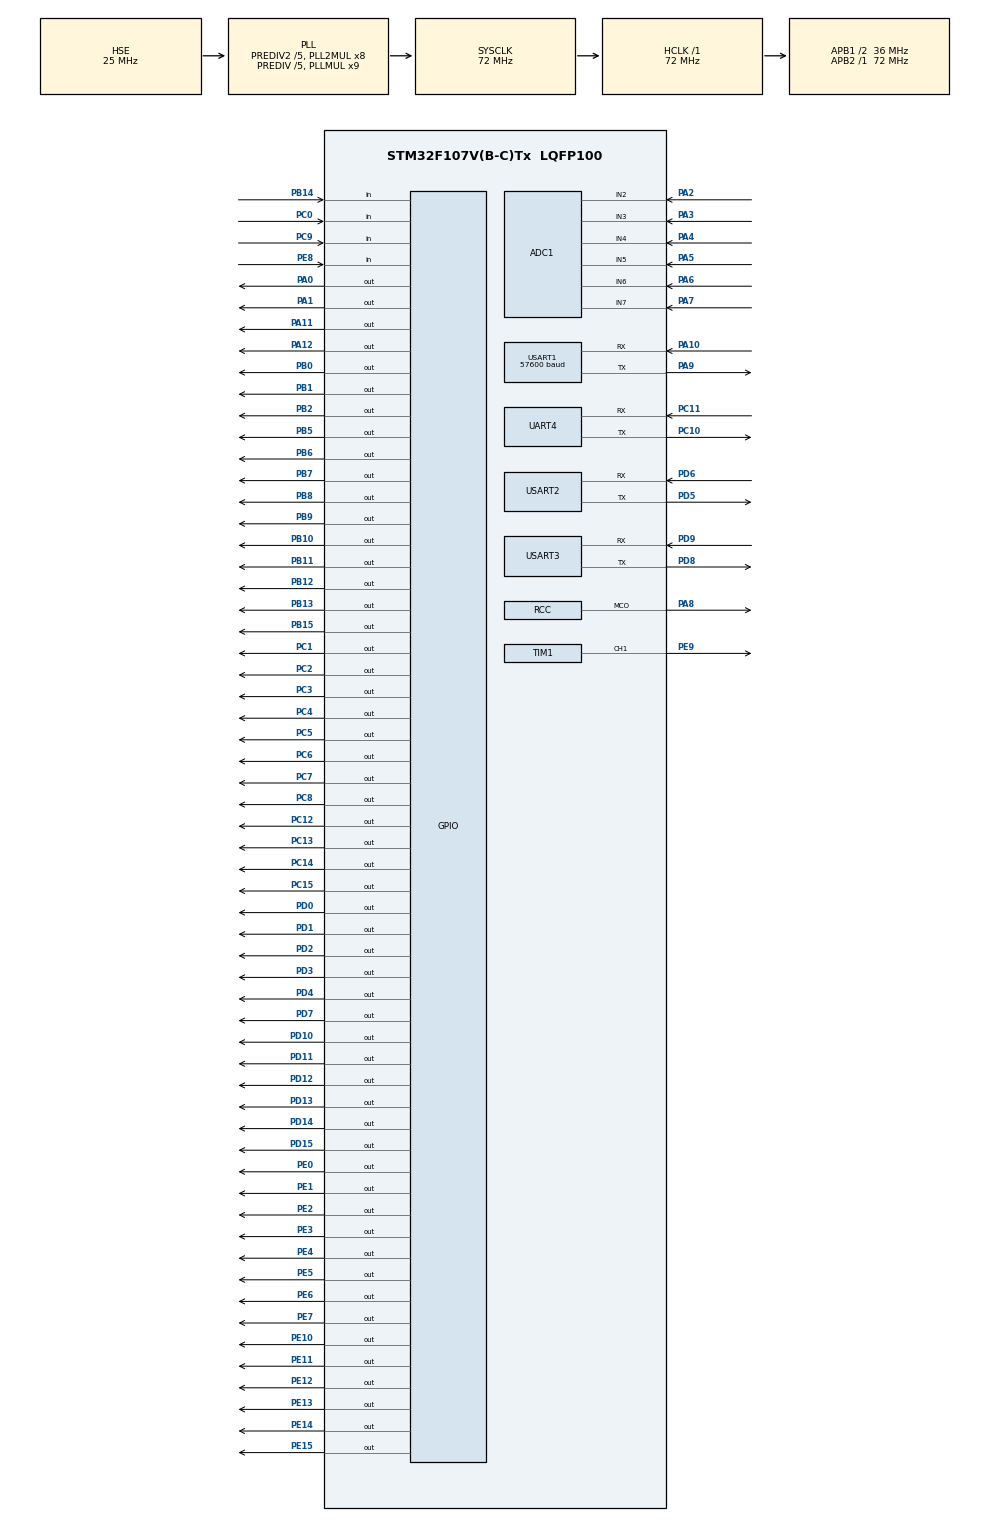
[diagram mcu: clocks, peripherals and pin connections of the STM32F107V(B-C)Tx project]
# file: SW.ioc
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ADC1.Channel-10\#ChannelRegularConversion=ADC_CHANNEL_6
ADC1.Channel-11\#ChannelRegularConversion=ADC_CHANNEL_7
ADC1.Channel-6\#ChannelRegularConversion=ADC_CHANNEL_2
ADC1.Channel-7\#ChannelRegularConversion=ADC_CHANNEL_3
ADC1.Channel-8\#ChannelRegularConversion=ADC_CHANNEL_4
ADC1.Channel-9\#ChannelRegularConversion=ADC_CHANNEL_5
ADC1.ContinuousConvMode=ENABLE
ADC1.EnableRegularConversion=ENABLE
ADC1.NbrOfConversion=6
ADC1.NbrOfConversionFlag=1
ADC1.Rank-10\#ChannelRegularConversion=5
ADC1.Rank-11\#ChannelRegularConversion=6
ADC1.Rank-6\#ChannelRegularConversion=1
ADC1.Rank-7\#ChannelRegularConversion=2
ADC1.Rank-8\#ChannelRegularConversion=3
ADC1.Rank-9\#ChannelRegularConversion=4
ADC1.SamplingTime-10\#ChannelRegularConversion=ADC_SAMPLETIME_41CYCLES_5
ADC1.SamplingTime-11\#ChannelRegularConversion=ADC_SAMPLETIME_41CYCLES_5
ADC1.SamplingTime-6\#ChannelRegularConversion=ADC_SAMPLETIME_41CYCLES_5
ADC1.SamplingTime-7\#ChannelRegularConversion=ADC_SAMPLETIME_41CYCLES_5
ADC1.SamplingTime-8\#ChannelRegularConversion=ADC_SAMPLETIME_41CYCLES_5
ADC1.SamplingTime-9\#ChannelRegularConversion=ADC_SAMPLETIME_41CYCLES_5
ADC1.master=1
Dma.ADC1.0.Direction=DMA_PERIPH_TO_MEMORY
Dma.ADC1.0.Instance=DMA1_Channel1
Dma.ADC1.0.MemDataAlignment=DMA_MDATAALIGN_WORD
Dma.ADC1.0.MemInc=DMA_MINC_ENABLE
Dma.ADC1.0.Mode=DMA_CIRCULAR
Dma.ADC1.0.PeriphDataAlignment=DMA_PDATAALIGN_WORD
Dma.ADC1.0.PeriphInc=DMA_PINC_DISABLE
Dma.ADC1.0.Priority=DMA_PRIORITY_LOW
Dma.Request0=ADC1
Mcu.Family=STM32F1
Mcu.Name=STM32F107V(B-C)Tx
Mcu.Package=LQFP100
NVIC.DMA1_Channel1_IRQn=true\:0\:0\:false\:false\:true\:true\:true
NVIC.PriorityGroup=NVIC_PRIORITYGROUP_4
NVIC.TIM3_IRQn=true\:0\:0\:false\:false\:true\:true\:true
NVIC.UART4_IRQn=true\:1\:0\:true\:true\:true\:2\:true\:true
NVIC.USART1_IRQn=true\:0\:0\:true\:true\:true\:1\:true\:true
NVIC.USART2_IRQn=true\:1\:0\:true\:true\:true\:3\:true\:true
NVIC.USART3_IRQn=true\:0\:0\:false\:true\:true\:4\:true\:true
OSC_IN.Mode=HSE-External-Oscillator
OSC_IN.Signal=RCC_OSC_IN
OSC_OUT.Mode=HSE-External-Oscillator
OSC_OUT.Signal=RCC_OSC_OUT
PA0-WKUP.Signal=GPIO_Output
PA1.Signal=GPIO_Output
PA10.Mode=Asynchronous
PA10.Signal=USART1_RX
PA11.Signal=GPIO_Output
PA12.Signal=GPIO_Output
PA13.Mode=Serial_Wire
PA13.Signal=SYS_JTMS-SWDIO
PA14.Mode=Serial_Wire
PA14.Signal=SYS_JTCK-SWCLK
PA15.Signal=SYS_JTDI
PA2.Signal=ADCx_IN2
PA3.Signal=ADCx_IN3
PA4.Signal=ADCx_IN4
PA5.Signal=ADCx_IN5
PA6.Signal=ADCx_IN6
PA7.Signal=ADCx_IN7
PA8.Mode=Clock-out
PA8.Signal=RCC_MCO
PA9.Mode=Asynchronous
PA9.Signal=USART1_TX
PB0.Signal=GPIO_Output
PB1.Signal=GPIO_Output
PB10.Signal=GPIO_Output
PB11.Signal=GPIO_Output
PB12.Signal=GPIO_Output
PB13.Signal=GPIO_Output
PB14.Signal=GPIO_Input
PB15.Signal=GPIO_Output
PB2.Signal=GPIO_Output
PB3.Signal=SYS_JTDO
PB4.Signal=SYS_NJTRST
PB5.Signal=GPIO_Output
PB6.Signal=GPIO_Output
PB7.Signal=GPIO_Output
PB8.Signal=GPIO_Output
PB9.Signal=GPIO_Output
PC0.Signal=GPIO_Input
PC1.Signal=GPIO_Output
PC10.Mode=Asynchronous
PC10.Signal=UART4_TX
PC11.Mode=Asynchronous
PC11.Signal=UART4_RX
PC12.Signal=GPIO_Output
PC13-TAMPER-RTC.Signal=GPIO_Output
PC14-OSC32_IN.Signal=GPIO_Output
PC15-OSC32_OUT.Signal=GPIO_Output
PC2.Signal=GPIO_Output
PC3.Signal=GPIO_Output
PC4.Signal=GPIO_Output
PC5.Signal=GPIO_Output
PC6.Signal=GPIO_Output
PC7.Signal=GPIO_Output
PC8.Signal=GPIO_Output
PC9.Signal=GPIO_Input
PD0.Signal=GPIO_Output
PD1.Signal=GPIO_Output
PD10.Signal=GPIO_Output
PD11.Signal=GPIO_Output
PD12.Signal=GPIO_Output
PD13.Signal=GPIO_Output
PD14.Signal=GPIO_Output
PD15.Signal=GPIO_Output
PD2.Signal=GPIO_Output
PD3.Signal=GPIO_Output
PD4.Signal=GPIO_Output
PD5.Mode=Asynchronous
PD5.Signal=USART2_TX
PD6.Mode=Asynchronous
PD6.Signal=USART2_RX
PD7.Signal=GPIO_Output
PD8.Mode=Asynchronous
PD8.Signal=USART3_TX
PD9.Mode=Asynchronous
PD9.Signal=USART3_RX
PE0.Signal=GPIO_Output
PE1.Signal=GPIO_Output
PE10.Signal=GPIO_Output
PE11.Signal=GPIO_Output
PE12.Signal=GPIO_Output
PE13.Signal=GPIO_Output
PE14.Signal=GPIO_Output
PE15.Signal=GPIO_Output
PE2.Signal=GPIO_Output
PE3.Signal=GPIO_Output
PE4.Signal=GPIO_Output
PE5.Signal=GPIO_Output
PE6.Signal=GPIO_Output
PE7.Signal=GPIO_Output
PE8.Signal=GPIO_Input
PE9.Signal=S_TIM1_CH1
ProjectManager.HeapSize=0x200
ProjectManager.StackSize=0x400
ProjectManager.TargetToolchain=MDK-ARM V5.27
RCC.ADCPresc=RCC_ADCPCLK2_DIV6
RCC.AHBFreq_Value=72000000
RCC.APB1CLKDivider=RCC_HCLK_DIV2
RCC.APB1Freq_Value=36000000
RCC.APB1TimFreq_Value=72000000
RCC.APB2Freq_Value=72000000
RCC.APB2TimFreq_Value=72000000
RCC.HCLKFreq_Value=72000000
RCC.HSEDivPLL=RCC_HSE_PREDIV_DIV5
RCC.HSE_VALUE=25000000
RCC.PLLMUL=RCC_PLL_MUL9
RCC.PLLSourceVirtual=RCC_PLLSOURCE_HSE
RCC.Prediv1Source=RCC_PREDIV1_SOURCE_PLL2
RCC.Prediv2=RCC_HSE_PREDIV2_DIV5
RCC.RCC_MCOSource=RCC_MCO1SOURCE_HSE
RCC.SYSCLKFreq_VALUE=72000000
RCC.SYSCLKSource=RCC_SYSCLKSOURCE_PLLCLK
RCC.USBFreq_Value=48000000
SH.ADCx_IN2.0=ADC1_IN2,IN2
SH.ADCx_IN3.0=ADC1_IN3,IN3
SH.ADCx_IN4.0=ADC1_IN4,IN4
SH.ADCx_IN5.0=ADC1_IN5,IN5
SH.ADCx_IN6.0=ADC1_IN6,IN6
SH.ADCx_IN7.0=ADC1_IN7,IN7
SH.S_TIM1_CH1.0=TIM1_CH1,PWM Generation1 CH1
TIM1.Channel-PWM\ Generation1\ CH1=TIM_CHANNEL_1
TIM3.Period=1500
TIM3.Prescaler=65000
UART4.VirtualMode=Asynchronous
USART1.BaudRate=57600
USART1.VirtualMode=VM_ASYNC
USART2.VirtualMode=VM_ASYNC
USART3.VirtualMode=VM_ASYNC
VP_TIM1_VS_ClockSourceINT.Mode=Internal
VP_TIM2_VS_ClockSourceINT.Mode=Internal
VP_TIM3_VS_ClockSourceINT.Mode=Internal
board=custom

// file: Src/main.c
/* USER CODE BEGIN Header */
/**
  ******************************************************************************
  * @file           : main.c
  * @brief          : Main program body
  ******************************************************************************
  * @attention
  *
  * <h2><center>&copy; Copyright (c) 2020 STMicroelectronics.
  * All rights reserved.</center></h2>
  *
  * This software component is licensed by ST under BSD 3-Clause license,
  * the "License"; You may not use this file except in compliance with the
  * License. You may obtain a copy of the License at:
  *                        opensource.org/licenses/BSD-3-Clause
  *
  ******************************************************************************
  */
/* USER CODE END Header */

#include "main.h"

/* USER CODE BEGIN Includes */
#include "bat.h"
#include "COM.h"
#include <stdio.h>
#include "motor.h"
#include "CMDHandler.h"
#include "lora.h"
/* USER CODE END Includes */

/* USER CODE BEGIN PD */

#define true 1
#define false 0

/* USER CODE END PD */

ADC_HandleTypeDef hadc1;
DMA_HandleTypeDef hdma_adc1;

TIM_HandleTypeDef htim1;
TIM_HandleTypeDef htim2;
TIM_HandleTypeDef htim3;

UART_HandleTypeDef huart4;
UART_HandleTypeDef huart1;
UART_HandleTypeDef huart2;
UART_HandleTypeDef huart3;

void SystemClock_Config(void);
static void MX_GPIO_Init(void);
static void MX_DMA_Init(void);
static void MX_ADC1_Init(void);
static void MX_TIM1_Init(void);
static void MX_UART4_Init(void);
static void MX_USART1_UART_Init(void);
static void MX_USART2_UART_Init(void);
static void MX_TIM2_Init(void);
static void MX_USART3_UART_Init(void);
static void MX_TIM3_Init(void);
static void MX_NVIC_Init(void);

/* USER CODE BEGIN 0 */
		//uint8_t rx_buff[1];
		char rx_ard_buff[1];
		char rx_add_buff[1];
		char rx_lora_buff[1];
		char rx_com_buff[1];
		uint32_t ADCvalues[6];
/* USER CODE END 0 */

int main(void)
{

  /* MCU Configuration--------------------------------------------------------*/

  /* Reset of all peripherals, Initializes the Flash interface and the Systick. */
  HAL_Init();

  /* Configure the system clock */
  SystemClock_Config();

  /* Initialize all configured peripherals */
  MX_GPIO_Init();
	MX_TIM3_Init();
  MX_DMA_Init();
  MX_ADC1_Init();
  MX_TIM1_Init();
  MX_UART4_Init();
  MX_USART1_UART_Init();
  MX_USART2_UART_Init();
  MX_TIM2_Init();
  MX_USART3_UART_Init();

  /* Initialize interrupts */
  MX_NVIC_Init();
  /* USER CODE BEGIN 2 */

	_Bool BATOKAY = false;

	//BatLED(0x3F);
	COM_TX("START\r\n");

	HAL_ADC_Start_DMA(&hadc1,(uint32_t *)ADCvalues, 6);
	//HAL_ADC_Start(&hadc1);
	//HAL_ADC_Start_IT(&hadc1);
	HAL_UART_Receive_IT(&huart1,(uint8_t*)rx_lora_buff,1);
	HAL_UART_Receive_IT(&huart2,(uint8_t*)rx_com_buff,1);
	HAL_UART_Receive_IT(&huart3,(uint8_t*)rx_add_buff,1);
	HAL_UART_Receive_IT(&huart4,(uint8_t*)rx_ard_buff,1);
	HAL_TIM_Base_Start_IT(&htim3);

	BatLED(0x00);
	ARD_TX("P");
	char onetimeloop = 1;
	char loop = 0;
	HAL_GPIO_WritePin(GPIOA, GPIO_PIN_11, GPIO_PIN_SET);
	/*MOTOR_3_RESET(1);
	MOTOR_3_SLEEP(1);
	MOTOR_3_BRAKE(0);
	MOTOR_3_DIR(0);
	MOTOR_3_ENABLE(1);
	MOTOR_3_CURRENT(10);*/

  /* USER CODE END 2 */

  /* Infinite loop */
  /* USER CODE BEGIN WHILE */
	/*while(!loop)
	{
		CH_HANDLER(0, "a",2);
		if(Ardunio_Ready(0))
			{
				loop = scheinwerfer(2);
			}
	}*/
  while(1)
  {
		if(onetimeloop)
		{
			if(Ardunio_Ready(0))
			{
				scheinwerfer(2);
			}

		}
		//scheinwerfer(2);

		if(SumBAT(ADCvalues))						//	Check Battery
		{															//
			BATOKAY = true;  						//
			/*
			{
				HAL_GPIO_WritePin(GPIOA, GPIO_PIN_11, GPIO_PIN_SET);
				MOTOR_STATE(1);
				MOTOR_INIT();
				onetimeloop = 0;
				//MOTOR_4_CURRENT(5);
			}
			if(MOTOR_FAULT())
			{

			}*/
		}															//
		else													//
		{															//
			BATOKAY = false;						//
			/*HAL_GPIO_WritePin(GPIOA, GPIO_PIN_11, GPIO_PIN_RESET);
			onetimeloop = 1;*/
		}															//

		Lora();
		LORA_HANDLER(0,"a");
		CH_HANDLER(0, "a",2);

		/*
		while(!BATOKAY || Lora_RxFlag(0,4))
		{

		}*/

  }

    /* USER CODE END WHILE */

}

void SystemClock_Config(void)
{
  RCC_OscInitTypeDef RCC_OscInitStruct = {0};
  RCC_ClkInitTypeDef RCC_ClkInitStruct = {0};
  RCC_PeriphCLKInitTypeDef PeriphClkInit = {0};

  /** Initializes the CPU, AHB and APB busses clocks
  */
  RCC_OscInitStruct.OscillatorType = RCC_OSCILLATORTYPE_HSE;
  RCC_OscInitStruct.HSEState = RCC_HSE_ON;
  RCC_OscInitStruct.HSEPredivValue = RCC_HSE_PREDIV_DIV5;
  RCC_OscInitStruct.HSIState = RCC_HSI_ON;
  RCC_OscInitStruct.Prediv1Source = RCC_PREDIV1_SOURCE_PLL2;
  RCC_OscInitStruct.PLL.PLLState = RCC_PLL_ON;
  RCC_OscInitStruct.PLL.PLLSource = RCC_PLLSOURCE_HSE;
  RCC_OscInitStruct.PLL.PLLMUL = RCC_PLL_MUL9;
  RCC_OscInitStruct.PLL2.PLL2State = RCC_PLL2_ON;
  RCC_OscInitStruct.PLL2.PLL2MUL = RCC_PLL2_MUL8;
  RCC_OscInitStruct.PLL2.HSEPrediv2Value = RCC_HSE_PREDIV2_DIV5;
  if (HAL_RCC_OscConfig(&RCC_OscInitStruct) != HAL_OK)
  {
    Error_Handler();
  }
  /** Initializes the CPU, AHB and APB busses clocks
  */
  RCC_ClkInitStruct.ClockType = RCC_CLOCKTYPE_HCLK|RCC_CLOCKTYPE_SYSCLK
                              |RCC_CLOCKTYPE_PCLK1|RCC_CLOCKTYPE_PCLK2;
  RCC_ClkInitStruct.SYSCLKSource = RCC_SYSCLKSOURCE_PLLCLK;
  RCC_ClkInitStruct.AHBCLKDivider = RCC_SYSCLK_DIV1;
  RCC_ClkInitStruct.APB1CLKDivider = RCC_HCLK_DIV2;
  RCC_ClkInitStruct.APB2CLKDivider = RCC_HCLK_DIV1;

  if (HAL_RCC_ClockConfig(&RCC_ClkInitStruct, FLASH_LATENCY_2) != HAL_OK)
  {
    Error_Handler();
  }
  PeriphClkInit.PeriphClockSelection = RCC_PERIPHCLK_ADC;
  PeriphClkInit.AdcClockSelection = RCC_ADCPCLK2_DIV6;
  if (HAL_RCCEx_PeriphCLKConfig(&PeriphClkInit) != HAL_OK)
  {
    Error_Handler();
  }
  HAL_RCC_MCOConfig(RCC_MCO, RCC_MCO1SOURCE_HSE, RCC_MCODIV_1);
  /** Configure the Systick interrupt time
  */
  __HAL_RCC_PLLI2S_ENABLE();
}

/**
  * @brief NVIC Configuration.
  * @retval None
  */
static void MX_NVIC_Init(void)
{
  /* USART1_IRQn interrupt configuration */
  HAL_NVIC_SetPriority(USART1_IRQn, 0, 0);
  HAL_NVIC_EnableIRQ(USART1_IRQn);
  /* UART4_IRQn interrupt configuration */
  HAL_NVIC_SetPriority(UART4_IRQn, 1, 0);
  HAL_NVIC_EnableIRQ(UART4_IRQn);
  /* USART2_IRQn interrupt configuration */
  HAL_NVIC_SetPriority(USART2_IRQn, 1, 0);
  HAL_NVIC_EnableIRQ(USART2_IRQn);
  /* USART3_IRQn interrupt configuration */
  HAL_NVIC_SetPriority(USART3_IRQn, 0, 0);
  HAL_NVIC_EnableIRQ(USART3_IRQn);
}

static void MX_ADC1_Init(void)
{

  ADC_ChannelConfTypeDef sConfig = {0};

  /** Common config
  */
  hadc1.Instance = ADC1;
  hadc1.Init.ScanConvMode = ADC_SCAN_ENABLE;
  hadc1.Init.ContinuousConvMode = ENABLE;
  hadc1.Init.DiscontinuousConvMode = DISABLE;
  hadc1.Init.ExternalTrigConv = ADC_SOFTWARE_START;
  hadc1.Init.DataAlign = ADC_DATAALIGN_RIGHT;
  hadc1.Init.NbrOfConversion = 6;
  if (HAL_ADC_Init(&hadc1) != HAL_OK)
  {
    Error_Handler();
  }
  /** Configure Regular Channel
  */
  sConfig.Channel = ADC_CHANNEL_2;
  sConfig.Rank = ADC_REGULAR_RANK_1;
  sConfig.SamplingTime = ADC_SAMPLETIME_41CYCLES_5;
  if (HAL_ADC_ConfigChannel(&hadc1, &sConfig) != HAL_OK)
  {
    Error_Handler();
  }
  /** Configure Regular Channel
  */
  sConfig.Channel = ADC_CHANNEL_3;
  sConfig.Rank = ADC_REGULAR_RANK_2;
  if (HAL_ADC_ConfigChannel(&hadc1, &sConfig) != HAL_OK)
  {
    Error_Handler();
  }
  /** Configure Regular Channel
  */
  sConfig.Channel = ADC_CHANNEL_4;
  sConfig.Rank = ADC_REGULAR_RANK_3;
  if (HAL_ADC_ConfigChannel(&hadc1, &sConfig) != HAL_OK)
  {
    Error_Handler();
  }
  /** Configure Regular Channel
  */
  sConfig.Channel = ADC_CHANNEL_5;
  sConfig.Rank = ADC_REGULAR_RANK_4;
  if (HAL_ADC_ConfigChannel(&hadc1, &sConfig) != HAL_OK)
  {
    Error_Handler();
  }
  /** Configure Regular Channel
  */
  sConfig.Channel = ADC_CHANNEL_6;
  sConfig.Rank = ADC_REGULAR_RANK_5;
  if (HAL_ADC_ConfigChannel(&hadc1, &sConfig) != HAL_OK)
  {
    Error_Handler();
  }
  /** Configure Regular Channel
  */
  sConfig.Channel = ADC_CHANNEL_7;
  sConfig.Rank = ADC_REGULAR_RANK_6;
  if (HAL_ADC_ConfigChannel(&hadc1, &sConfig) != HAL_OK)
  {
    Error_Handler();
  }

}

static void MX_TIM1_Init(void)
{

  TIM_ClockConfigTypeDef sClockSourceConfig = {0};
  TIM_MasterConfigTypeDef sMasterConfig = {0};
  TIM_OC_InitTypeDef sConfigOC = {0};
  TIM_BreakDeadTimeConfigTypeDef sBreakDeadTimeConfig = {0};

  htim1.Instance = TIM1;
  htim1.Init.Prescaler = 0;
  htim1.Init.CounterMode = TIM_COUNTERMODE_UP;
  htim1.Init.Period = 0;
  htim1.Init.ClockDivision = TIM_CLOCKDIVISION_DIV1;
  htim1.Init.RepetitionCounter = 0;
  htim1.Init.AutoReloadPreload = TIM_AUTORELOAD_PRELOAD_DISABLE;
  if (HAL_TIM_Base_Init(&htim1) != HAL_OK)
  {
    Error_Handler();
  }
  sClockSourceConfig.ClockSource = TIM_CLOCKSOURCE_INTERNAL;
  if (HAL_TIM_ConfigClockSource(&htim1, &sClockSourceConfig) != HAL_OK)
  {
    Error_Handler();
  }
  if (HAL_TIM_PWM_Init(&htim1) != HAL_OK)
  {
    Error_Handler();
  }
  sMasterConfig.MasterOutputTrigger = TIM_TRGO_RESET;
  sMasterConfig.MasterSlaveMode = TIM_MASTERSLAVEMODE_DISABLE;
  if (HAL_TIMEx_MasterConfigSynchronization(&htim1, &sMasterConfig) != HAL_OK)
  {
    Error_Handler();
  }
  sConfigOC.OCMode = TIM_OCMODE_PWM1;
  sConfigOC.Pulse = 0;
  sConfigOC.OCPolarity = TIM_OCPOLARITY_HIGH;
  sConfigOC.OCNPolarity = TIM_OCNPOLARITY_HIGH;
  sConfigOC.OCFastMode = TIM_OCFAST_DISABLE;
  sConfigOC.OCIdleState = TIM_OCIDLESTATE_RESET;
  sConfigOC.OCNIdleState = TIM_OCNIDLESTATE_RESET;
  if (HAL_TIM_PWM_ConfigChannel(&htim1, &sConfigOC, TIM_CHANNEL_1) != HAL_OK)
  {
    Error_Handler();
  }
  sBreakDeadTimeConfig.OffStateRunMode = TIM_OSSR_DISABLE;
  sBreakDeadTimeConfig.OffStateIDLEMode = TIM_OSSI_DISABLE;
  sBreakDeadTimeConfig.LockLevel = TIM_LOCKLEVEL_OFF;
  sBreakDeadTimeConfig.DeadTime = 0;
  sBreakDeadTimeConfig.BreakState = TIM_BREAK_DISABLE;
  sBreakDeadTimeConfig.BreakPolarity = TIM_BREAKPOLARITY_HIGH;
  sBreakDeadTimeConfig.AutomaticOutput = TIM_AUTOMATICOUTPUT_DISABLE;
  if (HAL_TIMEx_ConfigBreakDeadTime(&htim1, &sBreakDeadTimeConfig) != HAL_OK)
  {
    Error_Handler();
  }
  HAL_TIM_MspPostInit(&htim1);

}

static void MX_TIM2_Init(void)
{

  TIM_ClockConfigTypeDef sClockSourceConfig = {0};
  TIM_MasterConfigTypeDef sMasterConfig = {0};

  htim2.Instance = TIM2;
  htim2.Init.Prescaler = 0;
  htim2.Init.CounterMode = TIM_COUNTERMODE_UP;
  htim2.Init.Period = 0;
  htim2.Init.ClockDivision = TIM_CLOCKDIVISION_DIV1;
  htim2.Init.AutoReloadPreload = TIM_AUTORELOAD_PRELOAD_DISABLE;
  if (HAL_TIM_Base_Init(&htim2) != HAL_OK)
  {
    Error_Handler();
  }
  sClockSourceConfig.ClockSource = TIM_CLOCKSOURCE_INTERNAL;
  if (HAL_TIM_ConfigClockSource(&htim2, &sClockSourceConfig) != HAL_OK)
  {
    Error_Handler();
  }
  sMasterConfig.MasterOutputTrigger = TIM_TRGO_RESET;
  sMasterConfig.MasterSlaveMode = TIM_MASTERSLAVEMODE_DISABLE;
  if (HAL_TIMEx_MasterConfigSynchronization(&htim2, &sMasterConfig) != HAL_OK)
  {
    Error_Handler();
  }

}

static void MX_TIM3_Init(void)
{

  TIM_ClockConfigTypeDef sClockSourceConfig = {0};
  TIM_MasterConfigTypeDef sMasterConfig = {0};

  htim3.Instance = TIM3;
  htim3.Init.Prescaler = 65000;
  htim3.Init.CounterMode = TIM_COUNTERMODE_UP;
  htim3.Init.Period = 1500;
  htim3.Init.ClockDivision = TIM_CLOCKDIVISION_DIV1;
  htim3.Init.AutoReloadPreload = TIM_AUTORELOAD_PRELOAD_DISABLE;
  if (HAL_TIM_Base_Init(&htim3) != HAL_OK)
  {
    Error_Handler();
  }
  sClockSourceConfig.ClockSource = TIM_CLOCKSOURCE_INTERNAL;
  if (HAL_TIM_ConfigClockSource(&htim3, &sClockSourceConfig) != HAL_OK)
  {
    Error_Handler();
  }
  sMasterConfig.MasterOutputTrigger = TIM_TRGO_RESET;
  sMasterConfig.MasterSlaveMode = TIM_MASTERSLAVEMODE_DISABLE;
  if (HAL_TIMEx_MasterConfigSynchronization(&htim3, &sMasterConfig) != HAL_OK)
  {
    Error_Handler();
  }

}

static void MX_UART4_Init(void)
{

  huart4.Instance = UART4;
  huart4.Init.BaudRate = 115200;
  huart4.Init.WordLength = UART_WORDLENGTH_8B;
  huart4.Init.StopBits = UART_STOPBITS_1;
  huart4.Init.Parity = UART_PARITY_NONE;
  huart4.Init.Mode = UART_MODE_TX_RX;
  huart4.Init.HwFlowCtl = UART_HWCONTROL_NONE;
  huart4.Init.OverSampling = UART_OVERSAMPLING_16;
  if (HAL_UART_Init(&huart4) != HAL_OK)
  {
    Error_Handler();
  }

}

static void MX_USART1_UART_Init(void)
{

  huart1.Instance = USART1;
  huart1.Init.BaudRate = 57600;
  huart1.Init.WordLength = UART_WORDLENGTH_8B;
  huart1.Init.StopBits = UART_STOPBITS_1;
  huart1.Init.Parity = UART_PARITY_NONE;
  huart1.Init.Mode = UART_MODE_TX_RX;
  huart1.Init.HwFlowCtl = UART_HWCONTROL_NONE;
  huart1.Init.OverSampling = UART_OVERSAMPLING_16;
  if (HAL_UART_Init(&huart1) != HAL_OK)
  {
    Error_Handler();
  }

}

static void MX_USART2_UART_Init(void)
{

  huart2.Instance = USART2;
  huart2.Init.BaudRate = 115200;
  huart2.Init.WordLength = UART_WORDLENGTH_8B;
  huart2.Init.StopBits = UART_STOPBITS_1;
  huart2.Init.Parity = UART_PARITY_NONE;
  huart2.Init.Mode = UART_MODE_TX_RX;
  huart2.Init.HwFlowCtl = UART_HWCONTROL_NONE;
  huart2.Init.OverSampling = UART_OVERSAMPLING_16;
  if (HAL_UART_Init(&huart2) != HAL_OK)
  {
    Error_Handler();
  }

}

static void MX_USART3_UART_Init(void)
{

  huart3.Instance = USART3;
  huart3.Init.BaudRate = 115200;
  huart3.Init.WordLength = UART_WORDLENGTH_8B;
  huart3.Init.StopBits = UART_STOPBITS_1;
  huart3.Init.Parity = UART_PARITY_NONE;
  huart3.Init.Mode = UART_MODE_TX_RX;
  huart3.Init.HwFlowCtl = UART_HWCONTROL_NONE;
  huart3.Init.OverSampling = UART_OVERSAMPLING_16;
  if (HAL_UART_Init(&huart3) != HAL_OK)
  {
    Error_Handler();
  }

}

static void MX_DMA_Init(void)
{

  /* DMA controller clock enable */
  __HAL_RCC_DMA1_CLK_ENABLE();

  /* DMA interrupt init */
  /* DMA1_Channel1_IRQn interrupt configuration */
  HAL_NVIC_SetPriority(DMA1_Channel1_IRQn, 0, 0);
  HAL_NVIC_EnableIRQ(DMA1_Channel1_IRQn);

}

static void MX_GPIO_Init(void)
{
  GPIO_InitTypeDef GPIO_InitStruct = {0};

  /* GPIO Ports Clock Enable */
  __HAL_RCC_GPIOE_CLK_ENABLE();
  __HAL_RCC_GPIOC_CLK_ENABLE();
  __HAL_RCC_GPIOA_CLK_ENABLE();
  __HAL_RCC_GPIOB_CLK_ENABLE();
  __HAL_RCC_GPIOD_CLK_ENABLE();

  /*Configure GPIO pin Output Level */
  HAL_GPIO_WritePin(GPIOE, GPIO_PIN_2|GPIO_PIN_3|GPIO_PIN_4|GPIO_PIN_5
                          |GPIO_PIN_6|GPIO_PIN_7|GPIO_PIN_10|GPIO_PIN_11
                          |GPIO_PIN_12|GPIO_PIN_13|GPIO_PIN_14|GPIO_PIN_15
                          |GPIO_PIN_0|GPIO_PIN_1, GPIO_PIN_RESET);

  /*Configure GPIO pin Output Level */
  HAL_GPIO_WritePin(GPIOC, GPIO_PIN_13|GPIO_PIN_14|GPIO_PIN_15|GPIO_PIN_1
                          |GPIO_PIN_2|GPIO_PIN_3|GPIO_PIN_4|GPIO_PIN_5
                          |GPIO_PIN_6|GPIO_PIN_7|GPIO_PIN_8|GPIO_PIN_12, GPIO_PIN_RESET);

  /*Configure GPIO pin Output Level */
  HAL_GPIO_WritePin(GPIOA, GPIO_PIN_0|GPIO_PIN_1|GPIO_PIN_11|GPIO_PIN_12, GPIO_PIN_RESET);

  /*Configure GPIO pin Output Level */
  HAL_GPIO_WritePin(GPIOB, GPIO_PIN_0|GPIO_PIN_1|GPIO_PIN_2|GPIO_PIN_10
                          |GPIO_PIN_11|GPIO_PIN_12|GPIO_PIN_13|GPIO_PIN_15
                          |GPIO_PIN_5|GPIO_PIN_6|GPIO_PIN_7|GPIO_PIN_8
                          |GPIO_PIN_9, GPIO_PIN_RESET);

  /*Configure GPIO pin Output Level */
  HAL_GPIO_WritePin(GPIOD, GPIO_PIN_10|GPIO_PIN_11|GPIO_PIN_12|GPIO_PIN_13
                          |GPIO_PIN_14|GPIO_PIN_15|GPIO_PIN_0|GPIO_PIN_1
                          |GPIO_PIN_2|GPIO_PIN_3|GPIO_PIN_4|GPIO_PIN_7, GPIO_PIN_RESET);

  /*Configure GPIO pins : PE2 PE3 PE4 PE5
                           PE6 PE7 PE10 PE11
                           PE12 PE13 PE14 PE15
                           PE0 PE1 */
  GPIO_InitStruct.Pin = GPIO_PIN_2|GPIO_PIN_3|GPIO_PIN_4|GPIO_PIN_5
                          |GPIO_PIN_6|GPIO_PIN_7|GPIO_PIN_10|GPIO_PIN_11
                          |GPIO_PIN_12|GPIO_PIN_13|GPIO_PIN_14|GPIO_PIN_15
                          |GPIO_PIN_0|GPIO_PIN_1;
  GPIO_InitStruct.Mode = GPIO_MODE_OUTPUT_PP;
  GPIO_InitStruct.Pull = GPIO_NOPULL;
  GPIO_InitStruct.Speed = GPIO_SPEED_FREQ_LOW;
  HAL_GPIO_Init(GPIOE, &GPIO_InitStruct);

  /*Configure GPIO pins : PC13 PC14 PC15 PC1
                           PC2 PC3 PC4 PC5
                           PC6 PC7 PC8 PC12 */
  GPIO_InitStruct.Pin = GPIO_PIN_13|GPIO_PIN_14|GPIO_PIN_15|GPIO_PIN_1
                          |GPIO_PIN_2|GPIO_PIN_3|GPIO_PIN_4|GPIO_PIN_5
                          |GPIO_PIN_6|GPIO_PIN_7|GPIO_PIN_8|GPIO_PIN_12;
  GPIO_InitStruct.Mode = GPIO_MODE_OUTPUT_PP;
  GPIO_InitStruct.Pull = GPIO_NOPULL;
  GPIO_InitStruct.Speed = GPIO_SPEED_FREQ_LOW;
  HAL_GPIO_Init(GPIOC, &GPIO_InitStruct);

  /*Configure GPIO pins : PC0 PC9 */
  GPIO_InitStruct.Pin = GPIO_PIN_0|GPIO_PIN_9;
  GPIO_InitStruct.Mode = GPIO_MODE_INPUT;
  GPIO_InitStruct.Pull = GPIO_NOPULL;
  HAL_GPIO_Init(GPIOC, &GPIO_InitStruct);

  /*Configure GPIO pins : PA0 PA1 PA11 PA12 */
  GPIO_InitStruct.Pin = GPIO_PIN_0|GPIO_PIN_1|GPIO_PIN_11|GPIO_PIN_12;
  GPIO_InitStruct.Mode = GPIO_MODE_OUTPUT_PP;
  GPIO_InitStruct.Pull = GPIO_NOPULL;
  GPIO_InitStruct.Speed = GPIO_SPEED_FREQ_LOW;
  HAL_GPIO_Init(GPIOA, &GPIO_InitStruct);

  /*Configure GPIO pins : PB0 PB1 PB2 PB10
                           PB11 PB12 PB13 PB15
                           PB5 PB6 PB7 PB8
                           PB9 */
  GPIO_InitStruct.Pin = GPIO_PIN_0|GPIO_PIN_1|GPIO_PIN_2|GPIO_PIN_10
                          |GPIO_PIN_11|GPIO_PIN_12|GPIO_PIN_13|GPIO_PIN_15
                          |GPIO_PIN_5|GPIO_PIN_6|GPIO_PIN_7|GPIO_PIN_8
                          |GPIO_PIN_9;
  GPIO_InitStruct.Mode = GPIO_MODE_OUTPUT_PP;
  GPIO_InitStruct.Pull = GPIO_NOPULL;
  GPIO_InitStruct.Speed = GPIO_SPEED_FREQ_LOW;
  HAL_GPIO_Init(GPIOB, &GPIO_InitStruct);

  /*Configure GPIO pin : PE8 */
  GPIO_InitStruct.Pin = GPIO_PIN_8;
  GPIO_InitStruct.Mode = GPIO_MODE_INPUT;
  GPIO_InitStruct.Pull = GPIO_NOPULL;
  HAL_GPIO_Init(GPIOE, &GPIO_InitStruct);

  /*Configure GPIO pin : PB14 */
  GPIO_InitStruct.Pin = GPIO_PIN_14;
  GPIO_InitStruct.Mode = GPIO_MODE_INPUT;
  GPIO_InitStruct.Pull = GPIO_NOPULL;
  HAL_GPIO_Init(GPIOB, &GPIO_InitStruct);

  /*Configure GPIO pins : PD10 PD11 PD12 PD13
                           PD14 PD15 PD0 PD1
                           PD2 PD3 PD4 PD7 */
  GPIO_InitStruct.Pin = GPIO_PIN_10|GPIO_PIN_11|GPIO_PIN_12|GPIO_PIN_13
                          |GPIO_PIN_14|GPIO_PIN_15|GPIO_PIN_0|GPIO_PIN_1
                          |GPIO_PIN_2|GPIO_PIN_3|GPIO_PIN_4|GPIO_PIN_7;
  GPIO_InitStruct.Mode = GPIO_MODE_OUTPUT_PP;
  GPIO_InitStruct.Pull = GPIO_NOPULL;
  GPIO_InitStruct.Speed = GPIO_SPEED_FREQ_LOW;
  HAL_GPIO_Init(GPIOD, &GPIO_InitStruct);

  /*Configure GPIO pin : PA8 */
  GPIO_InitStruct.Pin = GPIO_PIN_8;
  GPIO_InitStruct.Mode = GPIO_MODE_AF_PP;
  GPIO_InitStruct.Speed = GPIO_SPEED_FREQ_LOW;
  HAL_GPIO_Init(GPIOA, &GPIO_InitStruct);

}

/* USER CODE BEGIN 4 */

void HAL_UART_RxCpltCallback(UART_HandleTypeDef *huart)
{
	if(huart->Instance==USART1)				//LORA
	{
		LORA_BUFFER(rx_lora_buff);
		HAL_UART_Receive_IT(&huart1,(uint8_t*)rx_lora_buff,1);
	}
	if(huart->Instance==USART2)				//COM
	{
		CH_BUFFER(rx_com_buff, 2);
		HAL_UART_Receive_IT(&huart2,(uint8_t*)rx_com_buff,1);
	}
	if(huart->Instance==USART3)				//ADDITIONAL
	{
		CH_BUFFER(rx_add_buff, 3);
		HAL_UART_Receive_IT(&huart3,(uint8_t*)rx_add_buff,1);
	}
	if(huart->Instance==UART4)				//ARDUINO
	{
		CH_BUFFER(rx_ard_buff, 4);
		HAL_UART_Receive_IT(&huart4,(uint8_t*)rx_ard_buff,1);
	}

	//singleChar = alpha[0];
	//CH_BUFFER(&singleChar);
}

void HAL_ADC_ConvCpltCallback( ADC_HandleTypeDef * hadc)
{
	HAL_ADC_Start_DMA(&hadc1,ADCvalues, 6);
	//HAL_ADC_Start(&hadc1);
}

void HAL_TIM_PeriodElapsedCallback(TIM_HandleTypeDef *htim)
{
	HAL_TIM_Base_Stop_IT(&htim3);
	HAL_TIM_Base_Start_IT(&htim3);
	//COM_TX("-------INT\r\n");
	//Timer_reached(1);
}

/* USER CODE END 4 */

void Error_Handler(void)
{
  /* USER CODE BEGIN Error_Handler_Debug */
  /* User can add his own implementation to report the HAL error return state */
	COM_TX("ERROR");
  /* USER CODE END Error_Handler_Debug */
}

/************************ (C) COPYRIGHT STMicroelectronics *****END OF FILE****/
